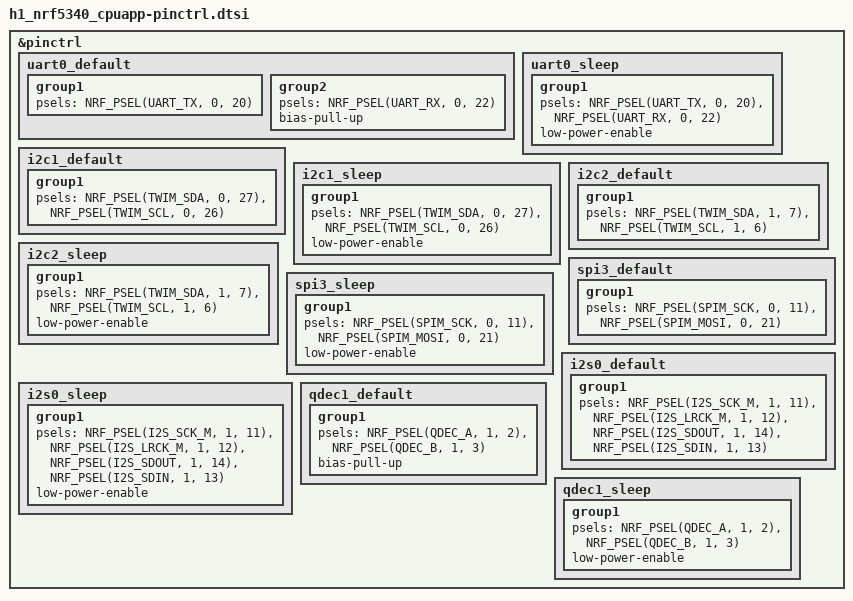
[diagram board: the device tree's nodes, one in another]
/*
 * Copyright (c) 2026 Troposound
 *
 * SPDX-License-Identifier: Apache-2.0
 */

&pinctrl {
	uart0_default: uart0_default {
		group1 {
			psels = <NRF_PSEL(UART_TX, 0, 20)>;
		};

		group2 {
			psels = <NRF_PSEL(UART_RX, 0, 22)>;
			bias-pull-up;
		};
	};

	uart0_sleep: uart0_sleep {
		group1 {
			psels = <NRF_PSEL(UART_TX, 0, 20)>,
				<NRF_PSEL(UART_RX, 0, 22)>;
			low-power-enable;
		};
	};

	i2c1_default: i2c1_default {
		group1 {
			psels = <NRF_PSEL(TWIM_SDA, 0, 27)>,
				<NRF_PSEL(TWIM_SCL, 0, 26)>;
		};
	};

	i2c1_sleep: i2c1_sleep {
		group1 {
			psels = <NRF_PSEL(TWIM_SDA, 0, 27)>,
				<NRF_PSEL(TWIM_SCL, 0, 26)>;
			low-power-enable;
		};
	};

	i2c2_default: i2c2_default {
		group1 {
			psels = <NRF_PSEL(TWIM_SDA, 1, 7)>,
				<NRF_PSEL(TWIM_SCL, 1, 6)>;
		};
	};

	i2c2_sleep: i2c2_sleep {
		group1 {
			psels = <NRF_PSEL(TWIM_SDA, 1, 7)>,
				<NRF_PSEL(TWIM_SCL, 1, 6)>;
			low-power-enable;
		};
	};

	spi3_default: spi3_default {
		group1 {
			psels = <NRF_PSEL(SPIM_SCK, 0, 11)>,
				<NRF_PSEL(SPIM_MOSI, 0, 21)>;
		};
	};

	spi3_sleep: spi3_sleep {
		group1 {
			psels = <NRF_PSEL(SPIM_SCK, 0, 11)>,
				<NRF_PSEL(SPIM_MOSI, 0, 21)>;
			low-power-enable;
		};
	};

	i2s0_default: i2s0_default {
		group1 {
			psels = <NRF_PSEL(I2S_SCK_M, 1, 11)>,
				<NRF_PSEL(I2S_LRCK_M, 1, 12)>,
				<NRF_PSEL(I2S_SDOUT, 1, 14)>,
				<NRF_PSEL(I2S_SDIN, 1, 13)>;
		};
	};

	i2s0_sleep: i2s0_sleep {
		group1 {
			psels = <NRF_PSEL(I2S_SCK_M, 1, 11)>,
				<NRF_PSEL(I2S_LRCK_M, 1, 12)>,
				<NRF_PSEL(I2S_SDOUT, 1, 14)>,
				<NRF_PSEL(I2S_SDIN, 1, 13)>;
			low-power-enable;
		};
	};

	qdec1_default: qdec1_default {
		group1 {
			psels = <NRF_PSEL(QDEC_A, 1, 2)>,
				<NRF_PSEL(QDEC_B, 1, 3)>;
			bias-pull-up;
		};
	};

	qdec1_sleep: qdec1_sleep {
		group1 {
			psels = <NRF_PSEL(QDEC_A, 1, 2)>,
				<NRF_PSEL(QDEC_B, 1, 3)>;
			low-power-enable;
		};
	};
};
